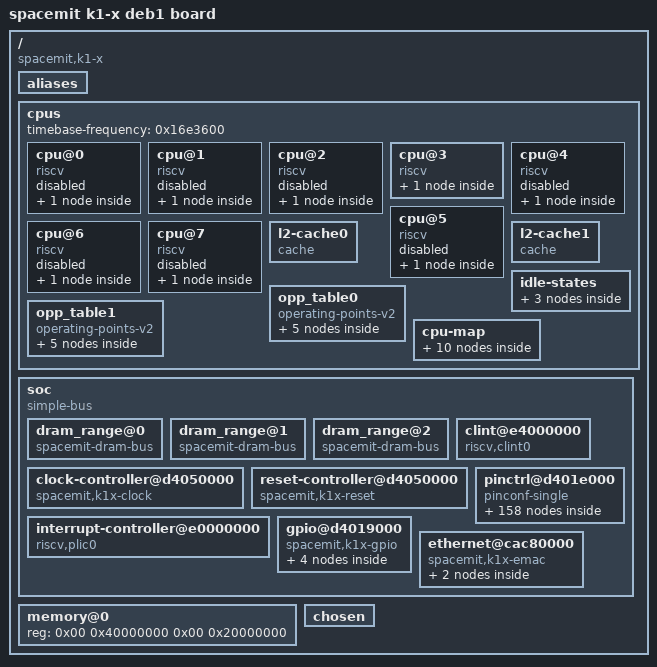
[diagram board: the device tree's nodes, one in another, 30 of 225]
/dts-v1/;

/ {
	compatible = "spacemit,k1-x";
	#address-cells = <0x02>;
	#size-cells = <0x02>;
	model = "spacemit k1-x deb1 board";
	modules_usrload = "8852bs";

	aliases {

	};

	cpus {
		#address-cells = <0x01>;
		#size-cells = <0x00>;
		timebase-frequency = <0x16e3600>;

		cpu@0 {
			compatible = "riscv";
			device_type = "cpu";
			model = "Spacemit(R) X60";
			reg = <0x00>;
			status = "disabled";
			riscv,isa = "rv64imafdcv_zicsr_zifencei_zicbom_zicboz_zicbop_zihintpause_zicond_zba_zbb_zbc_zbs_svpbmt_sstc_sscofpmf";
			riscv,cbom-block-size = <0x40>;
			i-cache-block-size = <0x40>;
			i-cache-size = <0x8000>;
			i-cache-sets = <0x200>;
			d-cache-block-size = <0x40>;
			d-cache-size = <0x8000>;
			d-cache-sets = <0x200>;
			next-level-cache = <0x01>;
			mmu-type = "riscv,sv39";
			clocks = <0x02 0x9c>;
			cpu-idle-states = <0x03>;
			operating-points-v2 = <0x04>;
			#cooling-cells = <0x02>;
			cpu-ai = "true";
			clst0-supply = <0x05>;
			vin-supply-names = "clst0";
			phandle = <0x08>;

			interrupt-controller {
				#interrupt-cells = <0x01>;
				compatible = "riscv,cpu-intc";
				interrupt-controller;
				phandle = <0x10>;
			};
		};

		cpu@1 {
			device_type = "cpu";
			reg = <0x01>;
			status = "disabled";
			compatible = "riscv";
			model = "Spacemit(R) X60";
			riscv,isa = "rv64imafdcv_zicsr_zifencei_zicbom_zicboz_zicbop_zihintpause_zicond_zba_zbb_zbc_zbs_svpbmt_sstc_sscofpmf";
			riscv,cbom-block-size = <0x40>;
			i-cache-block-size = <0x40>;
			i-cache-size = <0x8000>;
			i-cache-sets = <0x200>;
			d-cache-block-size = <0x40>;
			d-cache-size = <0x8000>;
			d-cache-sets = <0x200>;
			next-level-cache = <0x01>;
			mmu-type = "riscv,sv39";
			clocks = <0x02 0x9c>;
			cpu-idle-states = <0x03>;
			operating-points-v2 = <0x04>;
			#cooling-cells = <0x02>;
			cpu-ai = "true";
			phandle = <0x09>;

			interrupt-controller {
				#interrupt-cells = <0x01>;
				compatible = "riscv,cpu-intc";
				interrupt-controller;
				phandle = <0x11>;
			};
		};

		cpu@2 {
			device_type = "cpu";
			reg = <0x02>;
			status = "disabled";
			compatible = "riscv";
			model = "Spacemit(R) X60";
			riscv,isa = "rv64imafdcv_zicsr_zifencei_zicbom_zicboz_zicbop_zihintpause_zicond_zba_zbb_zbc_zbs_svpbmt_sstc_sscofpmf";
			riscv,cbom-block-size = <0x40>;
			i-cache-block-size = <0x40>;
			i-cache-size = <0x8000>;
			i-cache-sets = <0x200>;
			d-cache-block-size = <0x40>;
			d-cache-size = <0x8000>;
			d-cache-sets = <0x200>;
			next-level-cache = <0x01>;
			mmu-type = "riscv,sv39";
			clocks = <0x02 0x9c>;
			cpu-idle-states = <0x03>;
			operating-points-v2 = <0x04>;
			#cooling-cells = <0x02>;
			cpu-ai = "true";
			phandle = <0x0a>;

			interrupt-controller {
				#interrupt-cells = <0x01>;
				compatible = "riscv,cpu-intc";
				interrupt-controller;
				phandle = <0x12>;
			};
		};

		cpu@3 {
			device_type = "cpu";
			reg = <0x03>;
			status = "okay";
			compatible = "riscv";
			model = "Spacemit(R) X60";
			riscv,isa = "rv64imafdcv_zicsr_zifencei_zicbom_zicboz_zicbop_zihintpause_zicond_zba_zbb_zbc_zbs_svpbmt_sstc_sscofpmf";
			riscv,cbom-block-size = <0x40>;
			i-cache-block-size = <0x40>;
			i-cache-size = <0x8000>;
			i-cache-sets = <0x200>;
			d-cache-block-size = <0x40>;
			d-cache-size = <0x8000>;
			d-cache-sets = <0x200>;
			next-level-cache = <0x01>;
			mmu-type = "riscv,sv39";
			clocks = <0x02 0x9c>;
			cpu-idle-states = <0x03>;
			operating-points-v2 = <0x04>;
			#cooling-cells = <0x02>;
			cpu-ai = "true";
			phandle = <0x0b>;

			interrupt-controller {
				#interrupt-cells = <0x01>;
				compatible = "riscv,cpu-intc";
				interrupt-controller;
				phandle = <0x13>;
			};
		};

		cpu@4 {
			device_type = "cpu";
			reg = <0x04>;
			status = "disabled";
			compatible = "riscv";
			model = "Spacemit(R) X60";
			riscv,isa = "rv64imafdcv_zicsr_zifencei_zicbom_zicboz_zicbop_zihintpause_zicond_zba_zbb_zbc_zbs_svpbmt_sstc_sscofpmf";
			riscv,cbom-block-size = <0x40>;
			i-cache-block-size = <0x40>;
			i-cache-size = <0x8000>;
			i-cache-sets = <0x200>;
			d-cache-block-size = <0x40>;
			d-cache-size = <0x8000>;
			d-cache-sets = <0x200>;
			next-level-cache = <0x06>;
			mmu-type = "riscv,sv39";
			clocks = <0x02 0xa0>;
			cpu-idle-states = <0x03>;
			operating-points-v2 = <0x07>;
			#cooling-cells = <0x02>;
			phandle = <0x0c>;

			interrupt-controller {
				#interrupt-cells = <0x01>;
				compatible = "riscv,cpu-intc";
				interrupt-controller;
				phandle = <0x14>;
			};
		};

		cpu@5 {
			device_type = "cpu";
			reg = <0x05>;
			status = "disabled";
			compatible = "riscv";
			model = "Spacemit(R) X60";
			riscv,isa = "rv64imafdcv_zicsr_zifencei_zicbom_zicboz_zicbop_zihintpause_zicond_zba_zbb_zbc_zbs_svpbmt_sstc_sscofpmf";
			riscv,cbom-block-size = <0x40>;
			i-cache-block-size = <0x40>;
			i-cache-size = <0x8000>;
			i-cache-sets = <0x200>;
			d-cache-block-size = <0x40>;
			d-cache-size = <0x8000>;
			d-cache-sets = <0x200>;
			next-level-cache = <0x06>;
			mmu-type = "riscv,sv39";
			clocks = <0x02 0xa0>;
			cpu-idle-states = <0x03>;
			operating-points-v2 = <0x07>;
			#cooling-cells = <0x02>;
			phandle = <0x0d>;

			interrupt-controller {
				#interrupt-cells = <0x01>;
				compatible = "riscv,cpu-intc";
				interrupt-controller;
				phandle = <0x15>;
			};
		};

		cpu@6 {
			device_type = "cpu";
			reg = <0x06>;
			status = "disabled";
			compatible = "riscv";
			model = "Spacemit(R) X60";
			riscv,isa = "rv64imafdcv_zicsr_zifencei_zicbom_zicboz_zicbop_zihintpause_zicond_zba_zbb_zbc_zbs_svpbmt_sstc_sscofpmf";
			riscv,cbom-block-size = <0x40>;
			i-cache-block-size = <0x40>;
			i-cache-size = <0x8000>;
			i-cache-sets = <0x200>;
			d-cache-block-size = <0x40>;
			d-cache-size = <0x8000>;
			d-cache-sets = <0x200>;
			next-level-cache = <0x06>;
			mmu-type = "riscv,sv39";
			clocks = <0x02 0xa0>;
			cpu-idle-states = <0x03>;
			operating-points-v2 = <0x07>;
			#cooling-cells = <0x02>;
			phandle = <0x0e>;

			interrupt-controller {
				#interrupt-cells = <0x01>;
				compatible = "riscv,cpu-intc";
				interrupt-controller;
				phandle = <0x16>;
			};
		};

		cpu@7 {
			device_type = "cpu";
			reg = <0x07>;
			status = "disabled";
			compatible = "riscv";
			model = "Spacemit(R) X60";
			riscv,isa = "rv64imafdcv_zicsr_zifencei_zicbom_zicboz_zicbop_zihintpause_zicond_zba_zbb_zbc_zbs_svpbmt_sstc_sscofpmf";
			riscv,cbom-block-size = <0x40>;
			i-cache-block-size = <0x40>;
			i-cache-size = <0x8000>;
			i-cache-sets = <0x200>;
			d-cache-block-size = <0x40>;
			d-cache-size = <0x8000>;
			d-cache-sets = <0x200>;
			next-level-cache = <0x06>;
			mmu-type = "riscv,sv39";
			clocks = <0x02 0xa0>;
			cpu-idle-states = <0x03>;
			operating-points-v2 = <0x07>;
			#cooling-cells = <0x02>;
			phandle = <0x0f>;

			interrupt-controller {
				#interrupt-cells = <0x01>;
				compatible = "riscv,cpu-intc";
				interrupt-controller;
				phandle = <0x17>;
			};
		};

		l2-cache0 {
			compatible = "cache";
			cache-block-size = <0x40>;
			cache-level = <0x02>;
			cache-size = <0x80000>;
			cache-sets = <0x400>;
			cache-unified;
			phandle = <0x01>;
		};

		l2-cache1 {
			compatible = "cache";
			cache-block-size = <0x40>;
			cache-level = <0x02>;
			cache-size = <0x80000>;
			cache-sets = <0x400>;
			cache-unified;
			phandle = <0x06>;
		};

		idle-states {

			cpu-nonret {
				compatible = "riscv,idle-state";
				idle-state-name = "riscv,cpu-nonret";
				riscv,sbi-suspend-param = <0x90000000>;
				local-timer-stop;
				entry-latency-us = <0xc8>;
				exit-latency-us = <0x1f4>;
				min-residency-us = <0x3b6>;
				phandle = <0x03>;
			};

			cluster-nonret {
				compatible = "riscv,idle-state";
				idle-state-name = "riscv,cluster-nonret";
				riscv,sbi-suspend-param = <0x91000000>;
				local-timer-stop;
				entry-latency-us = <0x258>;
				exit-latency-us = <0x44c>;
				min-residency-us = <0xa8c>;
				wakeup-latency-us = <0x5dc>;
			};

			top-nonret {
				compatible = "riscv,idle-state";
				idle-state-name = "riscv,top-nonret";
				riscv,sbi-suspend-param = <0x92000000>;
				local-timer-stop;
				entry-latency-us = <0x2bc>;
				exit-latency-us = <0x4b0>;
				min-residency-us = <0xaf0>;
				wakeup-latency-us = <0x640>;
			};
		};

		opp_table0 {
			compatible = "operating-points-v2";
			opp-shared;
			clocks = <0x02 0x9d 0x02 0x9e 0x02 0x99>;
			clock-names = "ace\0tcm\0cci";
			cci-hz = <0x00 0x2498e580>;
			phandle = <0x04>;

			opp1600000000 {
				opp-hz = <0x00 0x5f5e1000>;
				tcm-hz = <0x00 0x2faf0800>;
				ace-hz = <0x00 0x2faf0800>;
				opp-microvolt = <0x100590>;
				clock-latency-ns = <0x30d40>;
			};

			opp1228800000 {
				opp-hz = <0x00 0x493e0000>;
				tcm-hz = <0x00 0x249f0000>;
				ace-hz = <0x00 0x249f0000>;
				opp-microvolt = <0xe7ef0>;
				clock-latency-ns = <0x30d40>;
			};

			opp1000000000 {
				opp-hz = <0x00 0x3b9aca00>;
				tcm-hz = <0x00 0x1dcd6500>;
				ace-hz = <0x00 0x1dcd6500>;
				opp-microvolt = <0xe7ef0>;
				clock-latency-ns = <0x30d40>;
			};

			opp819000000 {
				opp-hz = <0x00 0x30d0f2c0>;
				opp-microvolt = <0xe7ef0>;
				tcm-hz = <0x00 0x18687960>;
				ace-hz = <0x00 0x18687960>;
				clock-latency-ns = <0x30d40>;
			};

			opp614400000 {
				opp-hz = <0x00 0x249f0000>;
				tcm-hz = <0x00 0x124f8000>;
				ace-hz = <0x00 0x124f8000>;
				opp-microvolt = <0xe7ef0>;
				clock-latency-ns = <0x30d40>;
			};
		};

		opp_table1 {
			compatible = "operating-points-v2";
			opp-shared;
			clocks = <0x02 0xa1 0x02 0x99>;
			clock-names = "ace\0cci";
			cci-hz = <0x00 0x2498e580>;
			phandle = <0x07>;

			opp1600000000 {
				opp-hz = <0x00 0x5f5e1000>;
				ace-hz = <0x00 0x2faf0800>;
				opp-microvolt = <0x100590>;
				clock-latency-ns = <0x30d40>;
			};

			opp1228800000 {
				opp-hz = <0x00 0x493e0000>;
				ace-hz = <0x00 0x249f0000>;
				opp-microvolt = <0xe7ef0>;
				clock-latency-ns = <0x30d40>;
			};

			opp1000000000 {
				opp-hz = <0x00 0x3b9aca00>;
				ace-hz = <0x00 0x1dcd6500>;
				opp-microvolt = <0xe7ef0>;
				clock-latency-ns = <0x30d40>;
			};

			opp819000000 {
				opp-hz = <0x00 0x30d0f2c0>;
				ace-hz = <0x00 0x18687960>;
				opp-microvolt = <0xe7ef0>;
				clock-latency-ns = <0x30d40>;
			};

			opp614400000 {
				opp-hz = <0x00 0x249f0000>;
				ace-hz = <0x00 0x124f8000>;
				opp-microvolt = <0xe7ef0>;
				clock-latency-ns = <0x30d40>;
			};
		};

		cpu-map {

			cluster0 {

				core0 {
					cpu = <0x08>;
				};

				core1 {
					cpu = <0x09>;
				};

				core2 {
					cpu = <0x0a>;
				};

				core3 {
					cpu = <0x0b>;
				};
			};

			cluster1 {

				core0 {
					cpu = <0x0c>;
				};

				core1 {
					cpu = <0x0d>;
				};

				core2 {
					cpu = <0x0e>;
				};

				core3 {
					cpu = <0x0f>;
				};
			};
		};
	};

	soc {
		compatible = "simple-bus";
		#address-cells = <0x02>;
		#size-cells = <0x02>;
		ranges;

		dram_range@0 {
			compatible = "spacemit-dram-bus";
			#address-cells = <0x02>;
			#size-cells = <0x02>;
			dma-ranges = <0x00 0x00 0x00 0x00 0x00 0x80000000>;
			#interconnect-cells = <0x00>;
			status = "okay";
			phandle = <0x22>;
		};

		dram_range@1 {
			compatible = "spacemit-dram-bus";
			#address-cells = <0x02>;
			#size-cells = <0x02>;
			dma-ranges = <0x00 0x00 0x00 0x00 0x00 0x80000000 0x00 0x80000000 0x01 0x00 0x03 0x80000000>;
			#interconnect-cells = <0x00>;
			status = "okay";
			phandle = <0x3b>;
		};

		dram_range@2 {
			compatible = "spacemit-dram-bus";
			#address-cells = <0x02>;
			#size-cells = <0x02>;
			dma-ranges = <0x00 0x00 0x00 0x00 0x00 0x80000000 0x00 0xb8000000 0x01 0x38000000 0x03 0x48000000>;
			#interconnect-cells = <0x00>;
			status = "okay";
			phandle = <0x4e>;
		};

		clint@e4000000 {
			compatible = "riscv,clint0";
			interrupts-extended = <0x10 0x03 0x10 0x07 0x11 0x03 0x11 0x07 0x12 0x03 0x12 0x07 0x13 0x03 0x13 0x07 0x14 0x03 0x14 0x07 0x15 0x03 0x15 0x07 0x16 0x03 0x16 0x07 0x17 0x03 0x17 0x07>;
			reg = <0x00 0xe4000000 0x00 0x10000>;
		};

		clock-controller@d4050000 {
			compatible = "spacemit,k1x-clock";
			reg = <0x00 0xd4050000 0x00 0x209c 0x00 0xd4282800 0x00 0x400 0x00 0xd4015000 0x00 0x1000 0x00 0xd4090000 0x00 0x1000 0x00 0xd4282c00 0x00 0x400 0x00 0xd8440000 0x00 0x98 0x00 0xc0000000 0x00 0x4280 0x00 0xf0610000 0x00 0x20 0x00 0xc0880000 0x00 0x2050 0x00 0xc0888000 0x00 0x30>;
			reg-names = "mpmu\0apmu\0apbc\0apbs\0ciu\0dciu\0ddrc\0apbc2\0rcpu\0rcpu2";
			clocks = <0x18 0x19 0x1a 0x1b 0x1c>;
			clock-names = "vctcxo_24\0vctcxo_3\0vctcxo_1\0pll1_2457p6_vco\0clk_32k";
			#clock-cells = <0x01>;
			status = "okay";
			phandle = <0x02>;
		};

		reset-controller@d4050000 {
			compatible = "spacemit,k1x-reset";
			reg = <0x00 0xd4050000 0x00 0x209c 0x00 0xd4282800 0x00 0x400 0x00 0xd4015000 0x00 0x1000 0x00 0xd4090000 0x00 0x1000 0x00 0xd4282c00 0x00 0x400 0x00 0xd8440000 0x00 0x98 0x00 0xc0000000 0x00 0x4280 0x00 0xf0610000 0x00 0x20 0x00 0xc0880000 0x00 0x2050 0x00 0xc0888000 0x00 0x30>;
			reg-names = "mpmu\0apmu\0apbc\0apbs\0ciu\0dciu\0ddrc\0apbc2\0rcpu\0rcpu2";
			#reset-cells = <0x01>;
			status = "okay";
			phandle = <0x1f>;
		};

		interrupt-controller@e0000000 {
			#interrupt-cells = <0x01>;
			compatible = "riscv,plic0";
			interrupt-controller;
			interrupts-extended = <0x10 0x0b 0x10 0x09 0x11 0x0b 0x11 0x09 0x12 0x0b 0x12 0x09 0x13 0x0b 0x13 0x09 0x14 0x0b 0x14 0x09 0x15 0x0b 0x15 0x09 0x16 0x0b 0x16 0x09 0x17 0x0b 0x17 0x09>;
			reg = <0x00 0xe0000000 0x00 0x4000000>;
			reg-names = "control";
			riscv,max-priority = <0x07>;
			riscv,ndev = <0x9f>;
			phandle = <0x1e>;
		};

		pinctrl@d401e000 {
			compatible = "pinconf-single";
			reg = <0x00 0xd401e000 0x00 0x400>;
			#address-cells = <0x01>;
			#size-cells = <0x01>;
			#pinctrl-cells = <0x02>;
			#gpio-range-cells = <0x03>;
			pinctrl-single,register-width = <0x20>;
			pinctrl-single,function-mask = <0xff77>;
			pinctrl-single,gpio-range = <0x1d 0x32 0x02 0xc440 0x1d 0x3b 0x01 0xd040 0x1d 0x40 0x02 0xd040 0x1d 0x42 0x01 0xd040 0x1d 0x43 0x02 0xc440 0x1d 0x47 0x02 0xd041 0x1d 0x49 0x01 0xb041 0x1d 0x4a 0x01 0xd041 0x1d 0x4b 0x01 0xd040 0x1d 0x51 0x01 0xc440 0x1d 0x52 0x03 0xd040 0x1d 0x7f 0x01 0xb040 0x1d 0x80 0x02 0xd040 0x1d 0x78 0x01 0xb041 0x1d 0x79 0x01 0xa041 0x1d 0x74 0x01 0xb040 0x1d 0x83 0x01 0xb040 0x1d 0x85 0x01 0xb040 0x1d 0x86 0x01 0xb040 0x1d 0x87 0x01 0xb040 0x1d 0x88 0x01 0xd040 0x1d 0x8a 0x01 0xd040 0x1d 0x8f 0x01 0xa040 0x1d 0x90 0x01 0xd040 0x1d 0x91 0x03 0xb040>;
			phandle = <0x3a>;

			gpio-range {
				#pinctrl-single,gpio-range-cells = <0x03>;
				phandle = <0x1d>;
			};

			uart0_0_grp {
				pinctrl-single,pins = <0x1b8 0x03 0xc440 0x1bc 0x03 0xc440>;
			};

			uart0_1_grp {
				pinctrl-single,pins = <0x1c8 0x01 0xc440 0x144 0x03 0xa440>;
			};

			uart0_2_grp {
				pinctrl-single,pins = <0x114 0x02 0xb040 0x118 0x02 0xd040>;
				phandle = <0x23>;
			};

			uart2_grp {
				pinctrl-single,pins = <0x58 0x01 0xa040 0x5c 0x01 0xa040 0x60 0x01 0xa040 0x64 0x01 0xa040>;
				phandle = <0x24>;
			};

			uart3_0_grp {
				pinctrl-single,pins = <0x148 0x02 0xd040 0x14c 0x02 0xd040 0x150 0x02 0xd040 0x154 0x02 0xd040>;
			};

			uart3_1_grp {
				pinctrl-single,pins = <0x4c 0x02 0xd040 0x50 0x02 0xd040 0x54 0x02 0xd040 0x58 0x02 0xb040>;
			};

			uart3_2_grp {
				pinctrl-single,pins = <0xd8 0x04 0xb040 0xdc 0x04 0xd040 0xe0 0x04 0xd040 0xe4 0x04 0xd040>;
			};

			uart4_0_grp {
				pinctrl-single,pins = <0x16c 0x04 0xa440 0x168 0x04 0xa440>;
			};

			uart4_1_grp {
				pinctrl-single,pins = <0x148 0x03 0xd040 0x14c 0x03 0xd040 0x150 0x03 0xd040 0x154 0x03 0xd040>;
			};

			uart4_2_grp {
				pinctrl-single,pins = <0x60 0x02 0xb040 0x64 0x02 0xb040>;
			};

			uart4_3_grp {
				pinctrl-single,pins = <0x88 0x02 0xb040 0x8c 0x02 0xb040 0x90 0x02 0xb040 0x94 0x02 0xb040>;
			};

			uart4_4_grp {
				pinctrl-single,pins = <0x20c 0x04 0xb040 0x210 0x04 0xb040 0x214 0x04 0xb040 0x218 0x04 0xb040>;
			};

			uart5_0_grp {
				pinctrl-single,pins = <0x17c 0x03 0xa440 0x178 0x03 0xa440>;
			};

			uart5_1_grp {
				pinctrl-single,pins = <0x68 0x02 0xb040 0x6c 0x02 0xb040 0x70 0x02 0xb040 0x74 0x02 0xb040>;
			};

			uart5_2_grp {
				pinctrl-single,pins = <0xac 0x02 0xb040 0xb0 0x02 0xb040 0xb4 0x02 0xb040 0xb8 0x02 0xb040>;
			};

			uart5_3_grp {
				pinctrl-single,pins = <0x11c 0x04 0xd040 0x120 0x04 0xd040 0x124 0x04 0xb040 0x128 0x04 0xd040>;
			};

			uart6_0_grp {
				pinctrl-single,pins = <0x158 0x02 0xd040 0x1ec 0x02 0xd040 0x1f0 0x02 0xd040 0x1fc 0x02 0xb040>;
			};

			uart6_1_grp {
				pinctrl-single,pins = <0x04 0x02 0xb040 0x08 0x02 0xb040 0x0c 0x02 0xb040 0x10 0x02 0xb040>;
			};

			uart6_2_grp {
				pinctrl-single,pins = <0xe4 0x02 0xd040 0xe8 0x02 0xd040>;
			};

			uart7_0_grp {
				pinctrl-single,pins = <0x1f4 0x02 0xb040 0x1f8 0x02 0xb040>;
			};

			uart7_1_grp {
				pinctrl-single,pins = <0x14 0x02 0xb040 0x18 0x02 0xb040 0x1c 0x02 0xb040 0x20 0x02 0xb040>;
			};

			uart8_0_grp {
				pinctrl-single,pins = <0x14c 0x04 0xd040 0x150 0x04 0xd040>;
			};

			uart8_1_grp {
				pinctrl-single,pins = <0x24 0x02 0xb040 0x28 0x02 0xb040 0x2c 0x02 0xb040 0x30 0x02 0xb040>;
			};

			uart8_2_grp {
				pinctrl-single,pins = <0x130 0x04 0xc440 0x134 0x04 0xc440 0x138 0x04 0xc440 0x13c 0x04 0xc440>;
			};

			uart9_0_grp {
				pinctrl-single,pins = <0x34 0x02 0xb040 0x38 0x02 0xb040>;
			};

			uart9_1_grp {
				pinctrl-single,pins = <0x1d0 0x03 0xb040 0x21c 0x03 0xb040 0x220 0x03 0xb040 0x224 0x03 0xb040>;
			};

			uart9_2_grp {
				pinctrl-single,pins = <0x124 0x02 0xb040 0x128 0x02 0xd040>;
			};

			i2c0_grp {
				pinctrl-single,pins = <0xdc 0x01 0xc040 0xe0 0x01 0xc040>;
				phandle = <0x2d>;
			};

			i2c1_grp {
				pinctrl-single,pins = <0xe4 0x01 0xc040 0xe8 0x01 0xc040>;
				phandle = <0x2e>;
			};

			i2c2_0_grp {
				pinctrl-single,pins = <0x154 0x04 0xc040 0x158 0x04 0xc040>;
				phandle = <0x2f>;
			};

			i2c2_1_grp {
				pinctrl-single,pins = <0x11c 0x02 0xc040 0x120 0x02 0xc040>;
			};

			i2c2_2_grp {
				pinctrl-single,pins = <0x114 0x03 0xc040 0x118 0x03 0xc040>;
			};

			i2c3_0_grp {
				pinctrl-single,pins = <0x9c 0x02 0xc040 0xa0 0x02 0xc040>;
			};

			i2c3_1_grp {
				pinctrl-single,pins = <0xc0 0x04 0xc040 0xc4 0x04 0xc040>;
			};

			i2c3_2_grp {
				pinctrl-single,pins = <0x138 0x03 0xc040 0x13c 0x03 0xc040>;
				phandle = <0x31>;
			};

			i2c4_0_grp {
				pinctrl-single,pins = <0xa4 0x02 0xc040 0xa8 0x02 0xc040>;
			};

			i2c4_1_grp {
				pinctrl-single,pins = <0x130 0x05 0xc040 0x134 0x05 0xc040>;
			};

			i2c4_2_grp {
				pinctrl-single,pins = <0xd0 0x04 0xc040 0xd4 0x04 0xc040>;
				phandle = <0x32>;
			};

			i2c5_0_grp {
				pinctrl-single,pins = <0x148 0x05 0xc040 0x14c 0x05 0xc040>;
			};

			i2c5_1_grp {
				pinctrl-single,pins = <0xdc 0x05 0xc040 0xe0 0x05 0xc040>;
			};

			i2c6_0_grp {
				pinctrl-single,pins = <0x150 0x05 0xc040 0x1fc 0x05 0xa040>;
			};

			i2c6_1_grp {
				pinctrl-single,pins = <0x228 0x02 0xc040 0x22c 0x02 0xc040>;
			};

			i2c6_2_grp {
				pinctrl-single,pins = <0xe4 0x05 0xc040 0xe8 0x05 0xc040>;
				phandle = <0x33>;
			};

			i2c7_grp {
				pinctrl-single,pins = <0x228 0x01 0xc040 0x22c 0x01 0xa040>;
				phandle = <0x34>;
			};

			i2c8_grp {
				pinctrl-single,pins = <0x1d4 0x00 0xc040 0x1d8 0x00 0xc040>;
				phandle = <0x35>;
			};

			one_wire_0_grp {
				pinctrl-single,pins = <0x1d0 0x05 0xb040>;
			};

			one_wire_1_grp {
				pinctrl-single,pins = <0xc0 0x05 0xa440>;
			};

			ir_rx_0_grp {
				pinctrl-single,pins = <0x1e4 0x02 0xb040>;
			};

			ir_rx_1_grp {
				pinctrl-single,pins = <0x140 0x01 0xa440>;
			};

			ir_rx_2_grp {
				pinctrl-single,pins = <0xec 0x04 0xb040>;
			};

			pwm0_0_grp {
				pinctrl-single,pins = <0x1b8 0x05 0xc440>;
			};

			pwm0_1_grp {
				pinctrl-single,pins = <0x3c 0x03 0xb040>;
			};

			pwm0_2_grp {
				pinctrl-single,pins = <0x5c 0x04 0xb040>;
			};

			pwm1_0_grp {
				pinctrl-single,pins = <0x1bc 0x05 0xc440>;
			};

			pwm1_1_grp {
				pinctrl-single,pins = <0x78 0x03 0xb040>;
			};

			pwm1_2_grp {
				pinctrl-single,pins = <0x60 0x04 0xb040>;
			};

			pwm2_0_grp {
				pinctrl-single,pins = <0x1c0 0x05 0xc440>;
			};

			pwm2_1_grp {
				pinctrl-single,pins = <0x5c 0x02 0xb040>;
			};

			pwm2_2_grp {
				pinctrl-single,pins = <0x7c 0x03 0xb040>;
			};

			pwm2_3_grp {
				pinctrl-single,pins = <0x64 0x04 0xb040>;
			};

			pwm3_0_grp {
				pinctrl-single,pins = <0x1c4 0x05 0xc440>;
			};

			pwm3_1_grp {
				pinctrl-single,pins = <0x88 0x03 0xb040>;
			};

			pwm3_2_grp {
				pinctrl-single,pins = <0x68 0x04 0xb040>;
			};

			pwm4_0_grp {
				pinctrl-single,pins = <0x1c8 0x05 0xc440>;
			};

			pwm4_1_grp {
				pinctrl-single,pins = <0x8c 0x03 0xb040>;
			};

			pwm5_0_grp {
				pinctrl-single,pins = <0x1cc 0x05 0xc440>;
			};

			pwm5_1_grp {
				pinctrl-single,pins = <0x90 0x03 0xb040>;
			};

			pwm6_0_grp {
				pinctrl-single,pins = <0x1f4 0x04 0xb040>;
			};

			pwm6_1_grp {
				pinctrl-single,pins = <0x94 0x03 0xb040>;
			};

			pwm7_0_grp {
				pinctrl-single,pins = <0x204 0x02 0xd040>;
			};

			pwm7_1_grp {
				pinctrl-single,pins = <0x98 0x02 0xb040>;
			};

			pwm8_0_grp {
				pinctrl-single,pins = <0x04 0x03 0xb040>;
			};

			pwm8_1_grp {
				pinctrl-single,pins = <0x9c 0x04 0xd040>;
			};

			pwm9_0_grp {
				pinctrl-single,pins = <0x08 0x03 0xb040>;
			};

			pwm9_1_grp {
				pinctrl-single,pins = <0xa0 0x04 0xd040>;
			};

			pwm9_2_grp {
				pinctrl-single,pins = <0x12c 0x02 0xd040>;
			};

			pwm10_0_grp {
				pinctrl-single,pins = <0x0c 0x03 0xb040>;
			};

			pwm10_1_grp {
				pinctrl-single,pins = <0xa4 0x04 0xd040>;
			};

			pwm11_0_grp {
				pinctrl-single,pins = <0x10 0x03 0xb040>;
			};

			pwm11_1_grp {
				pinctrl-single,pins = <0xa8 0x04 0xd040>;
			};

			pwm12_0_grp {
				pinctrl-single,pins = <0x14 0x03 0xb040>;
			};

			pwm12_1_grp {
				pinctrl-single,pins = <0xac 0x04 0xb040>;
			};

			pwm13_0_grp {
				pinctrl-single,pins = <0x18 0x03 0xb040>;
			};

			pwm13_1_grp {
				pinctrl-single,pins = <0xb0 0x04 0xb040>;
			};

			pwm14_0_grp {
				pinctrl-single,pins = <0x1c 0x03 0xb040>;
			};

			pwm14_1_grp {
				pinctrl-single,pins = <0xb4 0x04 0xb040>;
				phandle = <0x38>;
			};

			pwm15_0_grp {
				pinctrl-single,pins = <0x20 0x03 0xb040>;
			};

			pwm15_1_grp {
				pinctrl-single,pins = <0xb8 0x04 0xb040>;
			};

			pwm16_0_grp {
				pinctrl-single,pins = <0x28 0x03 0xb040>;
			};

			pwm16_1_grp {
				pinctrl-single,pins = <0xbc 0x04 0xb040>;
			};

			pwm17_0_grp {
				pinctrl-single,pins = <0x2c 0x03 0xb040>;
			};

			pwm17_1_grp {
				pinctrl-single,pins = <0xd8 0x02 0xb040>;
			};

			pwm18_0_grp {
				pinctrl-single,pins = <0x30 0x03 0xb040>;
			};

			pwm18_1_grp {
				pinctrl-single,pins = <0xe8 0x04 0xd040>;
			};

			pwm19_0_grp {
				pinctrl-single,pins = <0x38 0x03 0xb040>;
			};

			pwm19_1_grp {
				pinctrl-single,pins = <0x100 0x04 0xb040>;
			};

			rpwm2_0_grp {
				pinctrl-single,pins = <0x140 0x02 0xa440>;
				phandle = <0x39>;
			};

			sspa0_0_grp {
				pinctrl-single,pins = <0x228 0x03 0xc040 0x22c 0x03 0xc040 0x230 0x03 0xa040 0x234 0x03 0xa040 0x238 0x03 0xa040>;
				phandle = <0x76>;
			};

			sspa0_1_grp {
				pinctrl-single,pins = <0xec 0x02 0xa040 0x20c 0x02 0xa040 0x210 0x02 0xa040 0x214 0x02 0xa040 0x218 0x02 0xa040>;
			};

			sspa1_grp {
				pinctrl-single,pins = <0x64 0x03 0xa040 0x68 0x01 0xa040 0x6c 0x01 0xa040 0x70 0x01 0xa040 0x74 0x01 0xa040>;
			};

			ssp2_0_grp {
				pinctrl-single,pins = <0x130 0x01 0xc440 0x134 0x01 0xc440 0x138 0x01 0xc440 0x13c 0x01 0xc440>;
			};

			ssp2_1_grp {
				pinctrl-single,pins = <0x104 0x03 0xc440 0x108 0x03 0xc440 0x10c 0x03 0xc440 0x110 0x03 0xc440>;
			};

			ssp3_0_grp {
				pinctrl-single,pins = <0x130 0x02 0xc440 0x134 0x02 0xc440 0x138 0x02 0xc440 0x13c 0x02 0xc440>;
			};

			ssp3_1_grp {
				pinctrl-single,pins = <0xf0 0x02 0xd040 0xf4 0x02 0xd040 0xf8 0x02 0xd040 0xfc 0x02 0xd040>;
			};

			qspi_grp {
				pinctrl-single,pins = <0x174 0x00 0xa440 0x170 0x00 0xa440 0x16c 0x00 0xa440 0x168 0x00 0xa440 0x17c 0x00 0xa440 0x178 0x00 0xc440>;
				phandle = <0x54>;
			};

			mmc1_grp {
				pinctrl-single,pins = <0x1b8 0x00 0xc440 0x1bc 0x00 0xc440 0x1c0 0x00 0xc440 0x1c4 0x00 0xc440 0x1c8 0x00 0xc440 0x1cc 0x00 0xa440>;
				phandle = <0x48>;
			};

			mmc1_fast_grp {
				pinctrl-single,pins = <0x1b8 0x00 0xd840 0x1bc 0x00 0xd840 0x1c0 0x00 0xd840 0x1c4 0x00 0xd840 0x1c8 0x00 0xd840 0x1cc 0x00 0xb840>;
				phandle = <0x49>;
			};

			mmc2_grp {
				pinctrl-single,pins = <0x40 0x01 0xd040 0x44 0x01 0xd040 0x48 0x01 0xd040 0x4c 0x01 0xd040 0x50 0x01 0xd040 0x54 0x01 0xd040>;
				phandle = <0x4c>;
			};

			usb0_0_grp {
				pinctrl-single,pins = <0x244 0x01 0xb040 0x248 0x01 0xb040 0x24c 0x01 0xb040>;
			};

			usb0_1_grp {
				pinctrl-single,pins = <0x104 0x01 0xb040 0x108 0x01 0xd040 0x100 0x01 0xb040>;
			};

			usb1_0_grp {
				pinctrl-single,pins = <0x240 0x01 0xb040>;
			};

			usb1_1_grp {
				pinctrl-single,pins = <0x10c 0x01 0xb040>;
			};

			usb2_0_grp {
				pinctrl-single,pins = <0x234 0x02 0xb040 0x238 0x02 0xb040 0x23c 0x01 0xb040>;
			};

			usb2_1_grp {
				pinctrl-single,pins = <0x114 0x01 0xb040 0x118 0x01 0xd040 0x110 0x01 0xb040>;
			};

			pcie0_0_grp {
				pinctrl-single,pins = <0x40 0x02 0xd040 0x44 0x02 0xd040 0x48 0x02 0xd040>;
			};

			pcie0_1_grp {
				pinctrl-single,pins = <0x78 0x04 0xb040 0x7c 0x04 0xb040 0x80 0x04 0xb040>;
			};

			pcie0_2_grp {
				pinctrl-single,pins = <0x1d0 0x04 0xb040 0x21c 0x04 0xb040 0x220 0x04 0xb040>;
			};

			pcie0_3_grp {
				pinctrl-single,pins = <0xd8 0x03 0xb040 0xdc 0x03 0xd040 0xe0 0x03 0xd040>;
			};

			pcie1_0_grp {
				pinctrl-single,pins = <0x40 0x04 0x1040 0x44 0x04 0x1040 0x48 0x04 0x1040>;
			};

			pcie1_1_grp {
				pinctrl-single,pins = <0x84 0x04 0xb040 0x88 0x04 0xb040 0x8c 0x04 0xb040>;
			};

			pcie1_2_grp {
				pinctrl-single,pins = <0xe4 0x03 0xd040 0xe8 0x03 0xd040 0xec 0x03 0xb040>;
			};

			pcie1_3_grp {
				pinctrl-single,pins = <0xf0 0x04 0xd040 0xf4 0x04 0xd040 0xf8 0x04 0xd040>;
				phandle = <0x51>;
			};

			pcie2_0_grp {
				pinctrl-single,pins = <0x4c 0x04 0xd040 0x50 0x04 0xd040 0x54 0x04 0xd040>;
			};

			pcie2_1_grp {
				pinctrl-single,pins = <0x90 0x04 0xb040 0x94 0x04 0xb040 0x98 0x04 0xb040>;
			};

			pcie2_2_grp {
				pinctrl-single,pins = <0xfc 0x04 0xd040 0x12c 0x04 0xd040 0x224 0x04 0xb040>;
			};

			pcie2_3_grp {
				pinctrl-single,pins = <0x20c 0x03 0xb040 0x210 0x03 0xb040 0x214 0x03 0xb040>;
			};

			pcie2_4_grp {
				pinctrl-single,pins = <0xfc 0x04 0xd040 0x210 0x03 0xd040 0x224 0x04 0xb040>;
				phandle = <0x53>;
			};

			gmac0_grp {
				pinctrl-single,pins = <0x04 0x01 0x1040 0x08 0x01 0x1040 0x0c 0x01 0x1040 0x10 0x01 0x1040 0x14 0x01 0x1040 0x18 0x01 0x1040 0x1c 0x01 0x1040 0x20 0x01 0x1040 0x24 0x01 0x1040 0x28 0x01 0x1040 0x2c 0x01 0x1040 0x30 0x01 0x1040 0x34 0x01 0x40 0x38 0x01 0x40 0x3c 0x01 0x1040 0xb8 0x01 0x1040>;
				phandle = <0x3c>;
			};

			gmac1_grp {
				pinctrl-single,pins = <0x78 0x01 0x1040 0x7c 0x01 0x1040 0x80 0x01 0x1040 0x84 0x01 0x1040 0x88 0x01 0x1040 0x8c 0x01 0x1040 0x90 0x01 0x40 0x94 0x01 0x40 0x98 0x01 0x1040 0x9c 0x01 0x40 0xa0 0x01 0x40 0xa4 0x01 0x40 0xa8 0x01 0x40 0xac 0x01 0x40 0xb0 0x01 0x1040 0xbc 0x01 0x1040>;
				phandle = <0x3f>;
			};

			can_0_grp {
				pinctrl-single,pins = <0x130 0x03 0xc440 0x134 0x03 0xc440>;
			};

			can_1_grp {
				pinctrl-single,pins = <0xdc 0x02 0xd040 0xe0 0x02 0xd040>;
			};

			hdmi_0_grp {
				pinctrl-single,pins = <0x1ec 0x01 0xd040 0x1f0 0x01 0xd040 0x1f4 0x01 0xb040 0x1f8 0x01 0xb040>;
				phandle = <0x63>;
			};

			hdmi_1_grp {
				pinctrl-single,pins = <0xf0 0x01 0xd040 0xf4 0x01 0xd040 0xf8 0x01 0xd040 0xfc 0x01 0xd040>;
			};

			spi_lcd_0_grp {
				pinctrl-single,pins = <0x1ec 0x03 0xd040 0x1f0 0x03 0xd040 0x1f4 0x03 0xb040 0x1f8 0x03 0xb040 0x1fc 0x03 0xb040 0x200 0x03 0xd040 0x204 0x03 0xd040>;
			};

			spi_lcd_1_grp {
				pinctrl-single,pins = <0x11c 0x03 0xd040 0x120 0x03 0xd040 0x124 0x03 0xb040 0x128 0x03 0xd040 0x12c 0x03 0xd040 0x218 0x03 0xb040 0x100 0x03 0xb040>;
			};

			camera0_grp {
				pinctrl-single,pins = <0xd8 0x01 0xb040>;
				phandle = <0x6d>;
			};

			camera1_grp {
				pinctrl-single,pins = <0xec 0x01 0xb040>;
				phandle = <0x72>;
			};

			camera2_grp {
				pinctrl-single,pins = <0x230 0x01 0xb040>;
			};

			pmic_grp {
				pinctrl-single,pins = <0x1dc 0x00 0xd040 0x1e0 0x00 0xb040 0x1e4 0x00 0xb040>;
			};

			mn_clk_0_grp {
				pinctrl-single,pins = <0x204 0x01 0xd040>;
			};

			mn_clk_1_grp {
				pinctrl-single,pins = <0x148 0x04 0xd040>;
			};

			mn_clk_2_grp {
				pinctrl-single,pins = <0xb4 0x01 0xb040>;
			};

			mn_clk_3_grp {
				pinctrl-single,pins = <0x54 0x03 0xd040>;
			};

			mn_clk_4_grp {
				pinctrl-single,pins = <0x60 0x03 0xb040>;
			};

			mn_clk_5_grp {
				pinctrl-single,pins = <0x84 0x03 0xb040>;
			};

			mn_clk2_0_grp {
				pinctrl-single,pins = <0x200 0x01 0xd040>;
			};

			mn_clk2_1_grp {
				pinctrl-single,pins = <0x158 0x03 0xd040>;
			};

			vcxo_0_grp {
				pinctrl-single,pins = <0x1e0 0x03 0xb040 0x1e4 0x03 0xb040>;
			};

			vcxo_1_grp {
				pinctrl-single,pins = <0x44 0x03 0xd040 0x48 0x03 0xd040>;
			};

			vcxo_2_grp {
				pinctrl-single,pins = <0x1f8 0x04 0xb040 0x1fc 0x04 0xb040>;
			};

			vcxo_out_0_grp {
				pinctrl-single,pins = <0x200 0x02 0xd040>;
			};

			vcxo_out_1_grp {
				pinctrl-single,pins = <0x34 0x03 0xb040>;
			};

			32k_out_0_grp {
				pinctrl-single,pins = <0x58 0x03 0xb040>;
			};

			32k_out_1_grp {
				pinctrl-single,pins = <0x80 0x03 0xb040>;
			};

			32k_out_2_grp {
				pinctrl-single,pins = <0x74 0x04 0xb040>;
			};

			pri_grp {
				pinctrl-single,pins = <0x11c 0x00 0xd040 0x120 0x00 0xd040 0x124 0x00 0xb040 0x128 0x00 0xd040>;
			};

			pinctrl_rcpu_grp {
				pinctrl-single,pins = <0xc0 0x01 0xc440 0xc4 0x01 0xc440>;
				phandle = <0x25>;
			};
		};

		gpio@d4019000 {
			compatible = "spacemit,k1x-gpio";
			reg = <0x00 0xd4019000 0x00 0x800>;
			gpio-controller;
			#gpio-cells = <0x02>;
			interrupts = <0x3a>;
			clocks = <0x02 0x43>;
			interrupt-names = "gpio_mux";
			interrupt-parent = <0x1e>;
			interrupt-controller;
			#interrupt-cells = <0x02>;
			gpio-ranges = <0x3a 0x31 0x32 0x02 0x3a 0x3a 0x3b 0x01 0x3a 0x3f 0x40 0x05 0x3a 0x46 0x47 0x04 0x3a 0x4a 0x4b 0x01 0x3a 0x50 0x51 0x04 0x3a 0x5a 0x7f 0x03 0x3a 0x60 0x78 0x02 0x3a 0x6e 0x74 0x01 0x3a 0x6f 0x83 0x01 0x3a 0x71 0x85 0x01 0x3a 0x72 0x86 0x03 0x3a 0x76 0x8a 0x01 0x3a 0x7b 0x8f 0x05>;
			phandle = <0x30>;

			gpio0 {
				reg-offset = <0x00>;
			};

			gpio1 {
				reg-offset = <0x04>;
			};

			gpio2 {
				reg-offset = <0x08>;
			};

			gpio3 {
				reg-offset = <0x100>;
			};
		};

		ethernet@cac80000 {
			compatible = "spacemit,k1x-emac";
			reg = <0x00 0xcac80000 0x00 0x420>;
			k1x,apmu-base-reg = <0xd4282800>;
			ctrl-reg = <0x3e4>;
			dline-reg = <0x3e8>;
			clocks = <0x02 0xa5 0x02 0xa6>;
			clock-names = "emac-clk\0ptp-clk";
			resets = <0x1f 0x5c>;
			reset-names = "emac-reset";
			interrupts = <0x83>;
			interrupt-parent = <0x1e>;
			mac-address = [00 00 00 00 00 00];
			ptp-support;
			ptp-clk-rate = <0x989680>;
			power-domains = <0x20 0x00>;
			clk,pm-runtime,no-sleep;
			cpuidle,pm-runtime,sleep;
			interconnects = <0x3b>;
			interconnect-names = "dma-mem";
			status = "okay";
			pinctrl-names = "default";
			pinctrl-0 = <0x3c>;
			emac,reset-gpio = <0x30 0x6e 0x00>;
			emac,reset-active-low;
			emac,reset-delays-us = <0x00 0x2710 0x186a0>;
			tx-threshold = <0x5ee>;
			rx-threshold = <0x0c>;
			tx-ring-num = <0x400>;
			rx-ring-num = <0x400>;
			dma-burst-len = <0x05>;
			ref-clock-from-phy;
			clk-tuning-enable;
			clk-tuning-by-delayline;
			tx-phase = <0x3c>;
			rx-phase = <0x49>;
			nvmem-cells = <0x3d>;
			nvmem-cell-names = "mac-address";
			phy-handle = <0x3e>;

			mdio-bus {
				#address-cells = <0x01>;
				#size-cells = <0x00>;

				phy@0 {
					compatible = "ethernet-phy-id001c.c916";
					device_type = "ethernet-phy";
					reg = <0x01>;
					phy-mode = "rgmii";
					phandle = <0x3e>;
				};
			};
		};
	};

	memory@0 {
		device_type = "memory";
		reg = <0x00 0x40000000 0x00 0x20000000>;
	};

	chosen {
		linux,initrd-end = <0x48317fcf>;
		linux,initrd-start = <0x48200000>;
		/* bootargs = "earlycon=sbi console=ttyS0,115200n8 debug loglevel=8 swiotlb=65536 rdinit=/init"; */
		bootargs = "earlycon=sbi console=hvc0 clk_ignore_unused debug loglevel=8,initcall_debug=1 root=/dev/vda";
		/* stdout-path = "serial0:115200n8";		 */
	};
};
